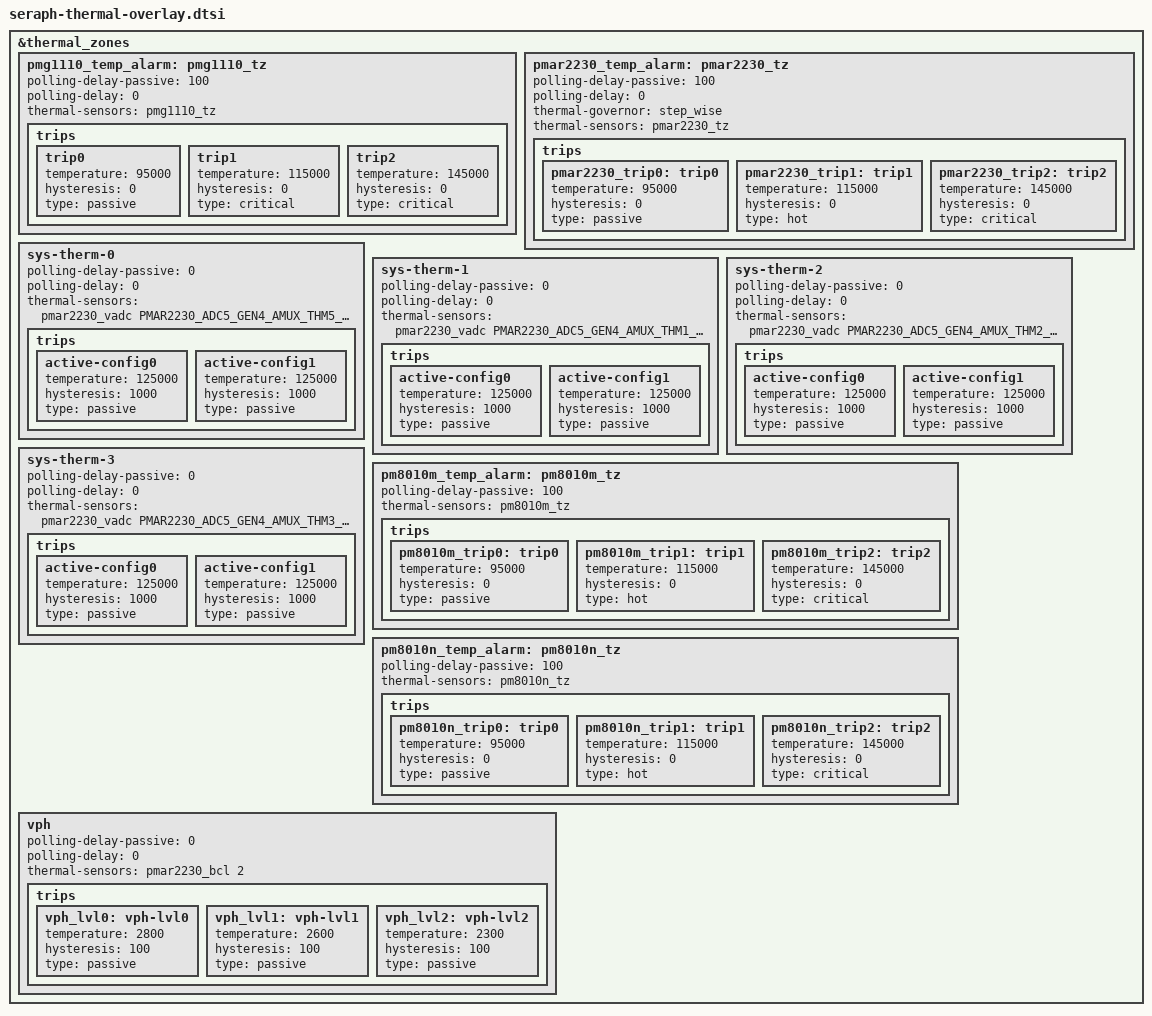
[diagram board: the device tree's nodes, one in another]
// SPDX-License-Identifier: BSD-3-Clause
/*
 * Copyright (c) Qualcomm Technologies, Inc. and/or its subsidiaries.
 */

#include <dt-bindings/thermal/thermal_qti.h>

&thermal_zones {
	pmg1110_temp_alarm: pmg1110_tz {
		polling-delay-passive = <100>;
		polling-delay = <0>;
		thermal-sensors = <&pmg1110_tz>;

		trips {
			trip0 {
				temperature = <95000>;
				hysteresis = <0>;
				type = "passive";
			};

			trip1 {
				temperature = <115000>;
				hysteresis = <0>;
				type = "critical";
			};

			trip2 {
				temperature = <145000>;
				hysteresis = <0>;
				type = "critical";
			};
		};
	};

	pmar2230_temp_alarm: pmar2230_tz {
		polling-delay-passive = <100>;
		polling-delay = <0>;
		thermal-governor = "step_wise";
		thermal-sensors = <&pmar2230_tz>;

		trips {
			pmar2230_trip0: trip0 {
				temperature = <95000>;
				hysteresis = <0>;
				type = "passive";
			};

			pmar2230_trip1: trip1 {
				temperature = <115000>;
				hysteresis = <0>;
				type = "hot";
			};

			pmar2230_trip2: trip2 {
				temperature = <145000>;
				hysteresis = <0>;
				type = "critical";
			};
		};
	};

	/* XO_THERM */
	sys-therm-0 {
		polling-delay-passive = <0>;
		polling-delay = <0>;
		thermal-sensors = <&pmar2230_vadc
				   PMAR2230_ADC5_GEN4_AMUX_THM5_XO_THERM_100K_PU>;

		trips {
			active-config0 {
				temperature = <125000>;
				hysteresis = <1000>;
				type = "passive";
			};

			active-config1 {
				temperature = <125000>;
				hysteresis = <1000>;
				type = "passive";
			};
		};
	};

	/* SOC_THERM */
	sys-therm-1 {
		polling-delay-passive = <0>;
		polling-delay = <0>;
		thermal-sensors = <&pmar2230_vadc
				   PMAR2230_ADC5_GEN4_AMUX_THM1_100K_PU>;

		trips {
			active-config0 {
				temperature = <125000>;
				hysteresis = <1000>;
				type = "passive";
			};

			active-config1 {
				temperature = <125000>;
				hysteresis = <1000>;
				type = "passive";
			};
		};
	};

	/* WLAN_PA_THERM */
	sys-therm-2 {
		polling-delay-passive = <0>;
		polling-delay = <0>;
		thermal-sensors = <&pmar2230_vadc
				   PMAR2230_ADC5_GEN4_AMUX_THM2_100K_PU>;

		trips {
			active-config0 {
				temperature = <125000>;
				hysteresis = <1000>;
				type = "passive";
			};

			active-config1 {
				temperature = <125000>;
				hysteresis = <1000>;
				type = "passive";
			};
		};
	};

	/* QUIET_THERM */
	sys-therm-3 {
		polling-delay-passive = <0>;
		polling-delay = <0>;
		thermal-sensors = <&pmar2230_vadc
				   PMAR2230_ADC5_GEN4_AMUX_THM3_100K_PU>;

		trips {
			active-config0 {
				temperature = <125000>;
				hysteresis = <1000>;
				type = "passive";
			};

			active-config1 {
				temperature = <125000>;
				hysteresis = <1000>;
				type = "passive";
			};
		};
	};

	pm8010m_temp_alarm: pm8010m_tz {
		polling-delay-passive = <100>;
		thermal-sensors = <&pm8010m_tz>;

		trips {
			pm8010m_trip0: trip0 {
				temperature = <95000>;
				hysteresis = <0>;
				type = "passive";
			};

			pm8010m_trip1: trip1 {
				temperature = <115000>;
				hysteresis = <0>;
				type = "hot";
			};

			pm8010m_trip2: trip2 {
				temperature = <145000>;
				hysteresis = <0>;
				type = "critical";
			};
		};
	};

	pm8010n_temp_alarm: pm8010n_tz {
		polling-delay-passive = <100>;
		thermal-sensors = <&pm8010n_tz>;

		trips {
			pm8010n_trip0: trip0 {
				temperature = <95000>;
				hysteresis = <0>;
				type = "passive";
			};

			pm8010n_trip1: trip1 {
				temperature = <115000>;
				hysteresis = <0>;
				type = "hot";
			};

			pm8010n_trip2: trip2 {
				temperature = <145000>;
				hysteresis = <0>;
				type = "critical";
			};
		};
	};

	vph {
		polling-delay-passive = <0>;
		polling-delay = <0>;
		thermal-sensors = <&pmar2230_bcl 2>;

		trips {
			vph_lvl0:vph-lvl0 {
				temperature = <2800>;
				hysteresis = <100>;
				type = "passive";
			};

			vph_lvl1:vph-lvl1 {
				temperature = <2600>;
				hysteresis = <100>;
				type = "passive";
			};

			vph_lvl2:vph-lvl2 {
				temperature = <2300>;
				hysteresis = <100>;
				type = "passive";
			};
		};
	};

};
